# AU302PDF51 register map
File version: 1.0
Registers are 32-bit, access per field, reset 0x0 unless marked. A register's access mark holds for its fields unless they carry their own. Offsets are from the block's base; [hi:lo] are bit positions; {n}, {i} and the like mark numbered series.

## CRG — CRG_PERIAPBIF peripheral interface
Base 0x10000000
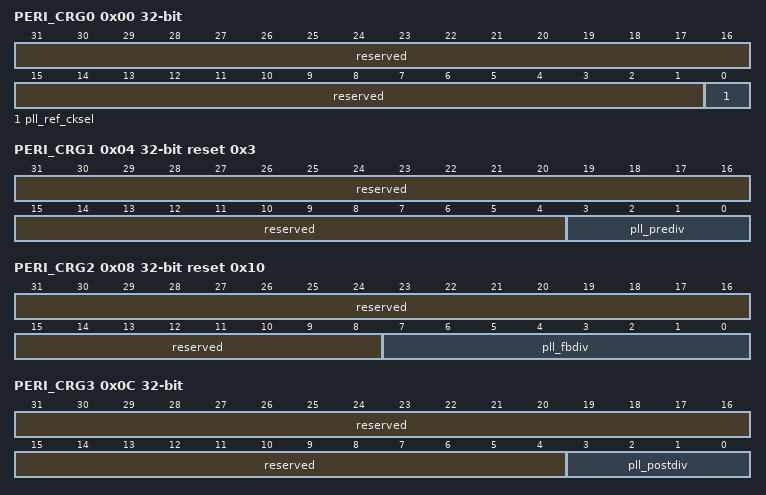
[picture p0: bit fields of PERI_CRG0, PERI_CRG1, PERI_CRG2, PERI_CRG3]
0x00 PERI_CRG0 — pll寄存器0。
  [31:1] reserved ro — 保留。
  [0] pll_ref_cksel rw — PLL输入参考时钟clk_pll_ref时钟源选择信号： 0：选择clk_hosc； 1：选择clk_xtal。
0x04 PERI_CRG1 reset 0x3 — pll寄存器1。
  [31:4] reserved ro — 保留。
  [3:0] pll_prediv rw — PLL内部前置分频器分频比 0x0：1； 0x1：1； 0x2：2； 0x3：4； 其他：保留。
0x08 PERI_CRG2 reset 0x10 — pll寄存器2。
  [31:8] reserved ro — 保留。
  [7:0] pll_fbdiv rw — PLL内部反馈分频器分频比 允许配置范围8'd6 ~ 8'd63； 其他：保留。
0x0C PERI_CRG3 — pll寄存器3。
  [31:4] reserved ro — 保留。
  [3:0] pll_postdiv rw — PLL内部后置分频器分频比 0x0：1； 0x1：2； 0x2：4； 0x3：8； 0x4：16； 0x5：32； 其他：保留。
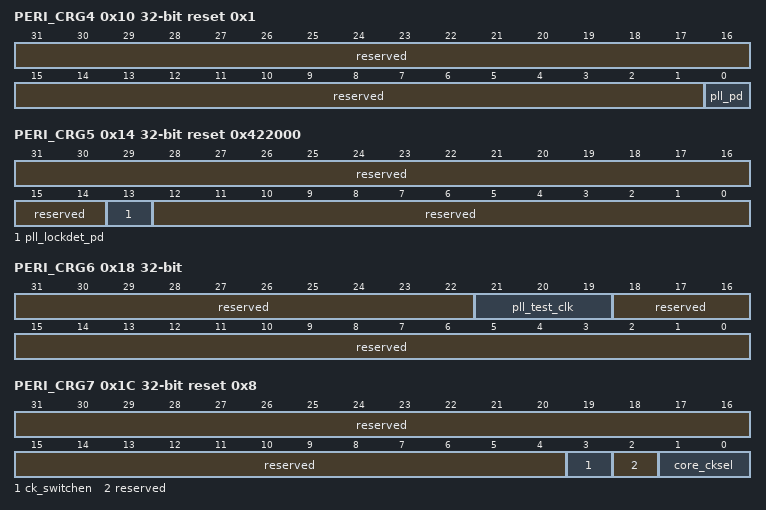
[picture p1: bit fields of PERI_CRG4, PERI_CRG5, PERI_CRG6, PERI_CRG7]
0x10 PERI_CRG4 reset 0x1 — pll寄存器4。
  [31:1] reserved ro — 保留。
  [0] pll_pd rw — PLL使能控制 0：PLL上电使能； 1：PLL下电关闭。
0x14 PERI_CRG5 reset 0x422000 — pll寄存器5。
  [31:14] reserved ro — 保留。
  [13] pll_lockdet_pd rw — PLL锁定检测控制 0：PLL锁定检测使能； 1：PLL锁定检测关闭。 PLL下电关闭时时需关闭锁定检测，PLL上电使能后需打开锁定检测。
  [12:0] reserved ro — 保留。
0x18 PERI_CRG6 — pll寄存器6。
  [31:22] reserved ro — 保留。
  [21:19] pll_test_clk rw — CLKOUT_TEST测试口输出功能选择： 3'd0:FPFD 信号 3'd1:CKFB 信号 3'd2:锁定检测器输出信号 3'd3:FOUTPOSTDIV的128分频输出信号 3'd4:未分配，输出0 3'd5:未分配，输出0 3'd6:未分配，输出0 3'd7:未分配，输出0
  [18:0] reserved ro — 保留；
0x1C PERI_CRG7 reset 0x8 — 系统时钟控制寄存器。
  [31:4] reserved ro — 保留。
  [3] ck_switchen rw — 时钟切换交互功能使能： 0：不使能； 1：使能。
  [2] reserved ro — 保留；
  [1:0] core_cksel rw — core_cksel信号： 00：选择clk_hosc； 01：旋转clk_xtal； 10：选择clk_pll； 11:保留。
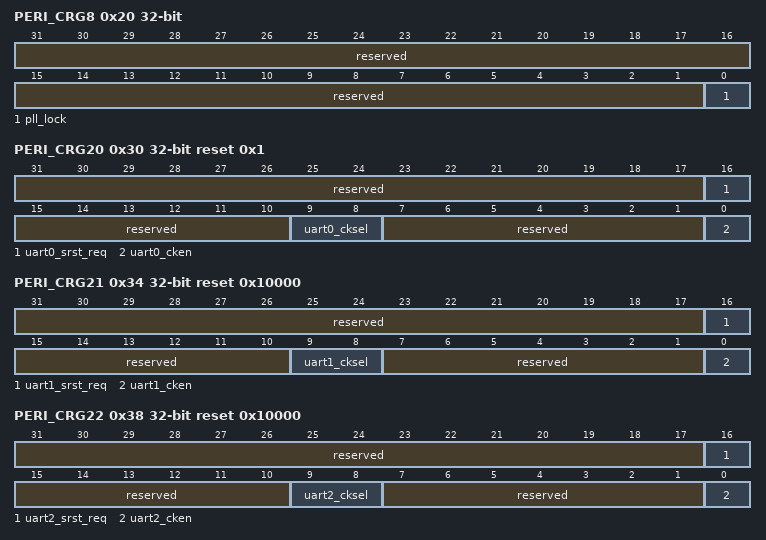
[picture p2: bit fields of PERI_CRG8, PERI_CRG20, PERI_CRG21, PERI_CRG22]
0x20 PERI_CRG8 ro — pll输出lock信息寄存器。
  [31:1] reserved — 保留。
  [0] pll_lock — pll lock信号：
0x30 PERI_CRG20 reset 0x1 — uart0时钟及软复位控制寄存器。
  [31:17] reserved ro — 保留。
  [16] uart0_srst_req rw — uart0软复位请求： 0：不复位； 1：复位。
  [15:10] reserved ro — 保留。
  [9:8] uart0_cksel rw — uart0时钟选择信号： 00：选择clk_ls时钟； 01：选择clk_ls/2时钟； 10：选择clk_ls/4时钟； 11：选择clk_ls/8时钟。
  [7:1] reserved ro — 保留。
  [0] uart0_cken rw — uart0时钟门控： 0：关断； 1：打开。
0x34 PERI_CRG21 reset 0x10000 — uart1时钟及软复位控制寄存器。
  [31:17] reserved ro — 保留。
  [16] uart1_srst_req rw — uart1软复位请求： 0：不复位； 1：复位。
  [15:10] reserved ro — 保留。
  [9:8] uart1_cksel rw — uart1时钟选择信号： 00：选择clk_ls时钟； 01：选择clk_ls/2时钟； 10：选择clk_ls/4时钟； 11：选择clk_ls/8时钟。
  [7:1] reserved ro — 保留。
  [0] uart1_cken rw — uart1时钟门控： 0：关断； 1：打开。
0x38 PERI_CRG22 reset 0x10000 — uart2时钟及软复位控制寄存器。
  [31:17] reserved ro — 保留。
  [16] uart2_srst_req rw — uart2软复位请求： 0：不复位； 1：复位。
  [15:10] reserved ro — 保留。
  [9:8] uart2_cksel rw — uart2时钟选择信号： 00：选择clk_ls时钟； 01：选择clk_ls/2时钟； 10：选择clk_ls/4时钟； 11：选择clk_ls/8时钟。
  [7:1] reserved ro — 保留。
  [0] uart2_cken rw — uart2时钟门控： 0：关断； 1：打开。
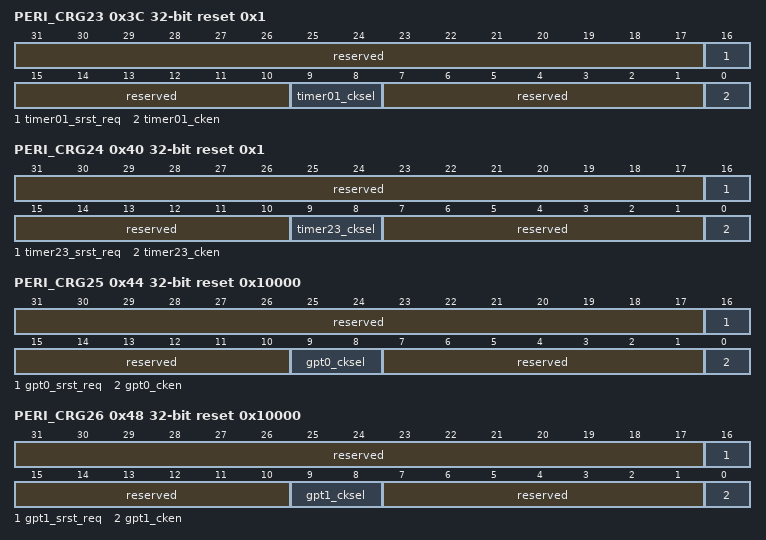
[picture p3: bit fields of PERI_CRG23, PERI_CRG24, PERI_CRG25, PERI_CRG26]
0x3C PERI_CRG23 reset 0x1 — timer0/1时钟及软复位控制寄存器。
  [31:17] reserved ro — 保留。
  [16] timer01_srst_req rw — timer0/1软复位请求： 0：不复位； 1：复位。
  [15:10] reserved ro — 保留。
  [9:8] timer01_cksel rw — timer0/1时钟选择信号： 00：选择clk_ls时钟； 01：选择clk_ls/2时钟； 10：选择clk_ls/4时钟； 11：选择clk_ls/8时钟。
  [7:1] reserved ro — 保留。
  [0] timer01_cken rw — timer0/1时钟门控： 0：关断； 1：打开。
0x40 PERI_CRG24 reset 0x1 — timer2/3时钟及软复位控制寄存器。
  [31:17] reserved ro — 保留。
  [16] timer23_srst_req rw — timer2/3软复位请求： 0：不复位； 1：复位。
  [15:10] reserved ro — 保留。
  [9:8] timer23_cksel rw — timer2/3时钟选择信号： 00：选择clk_ls时钟； 01：选择clk_ls/2时钟； 10：选择clk_ls/4时钟； 11：选择clk_ls/8时钟。
  [7:1] reserved ro — 保留。
  [0] timer23_cken rw — timer2/3时钟门控： 0：关断； 1：打开。
0x44 PERI_CRG25 reset 0x10000 — gpt0时钟及软复位控制寄存器。
  [31:17] reserved ro — 保留。
  [16] gpt0_srst_req rw — gpt0软复位请求： 0：不复位； 1：复位。
  [15:10] reserved ro — 保留。
  [9:8] gpt0_cksel rw — gpt0时钟选择信号： 00：选择clk_ls时钟； 01：选择clk_ls/2时钟； 10：选择clk_ls/4时钟； 11：选择clk_ls/8时钟。
  [7:1] reserved ro — 保留。
  [0] gpt0_cken rw — gpt0时钟门控： 0：关断； 1：打开。
0x48 PERI_CRG26 reset 0x10000 — gpt1时钟及软复位控制寄存器。
  [31:17] reserved ro — 保留。
  [16] gpt1_srst_req rw — gpt1软复位请求： 0：不复位； 1：复位。
  [15:10] reserved ro — 保留。
  [9:8] gpt1_cksel rw — gpt1时钟选择信号： 00：选择clk_ls时钟； 01：选择clk_ls/2时钟； 10：选择clk_ls/4时钟； 11：选择clk_ls/8时钟。
  [7:1] reserved ro — 保留。
  [0] gpt1_cken rw — gpt1时钟门控： 0：关断； 1：打开。
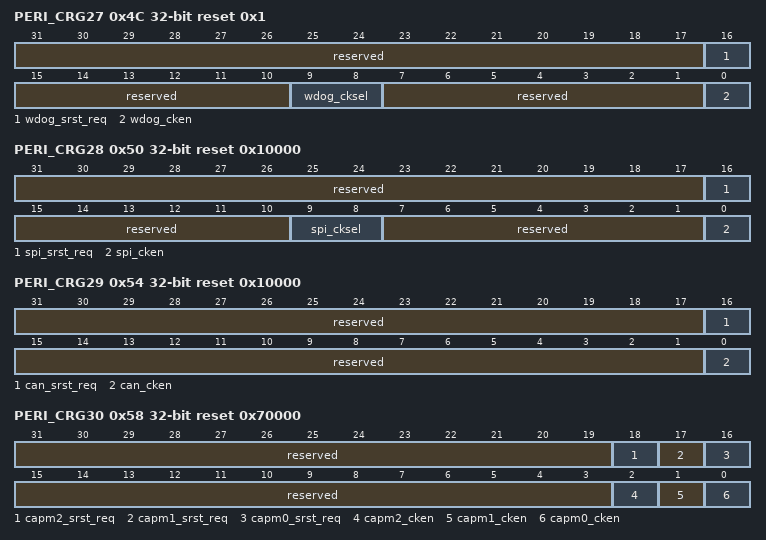
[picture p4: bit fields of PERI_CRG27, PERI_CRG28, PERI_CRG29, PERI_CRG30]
0x4C PERI_CRG27 reset 0x1 — wdog时钟及软复位控制寄存器。
  [31:17] reserved ro — 保留。
  [16] wdog_srst_req rw — wdog软复位请求： 0：不复位； 1：复位。
  [15:10] reserved ro — 保留。
  [9:8] wdog_cksel rw — wdog时钟选择信号： 00：选择clk_ls时钟； 01：选择clk_ls/2时钟； 10：选择clk_ls/4时钟； 11：选择clk_ls/8时钟。
  [7:1] reserved ro — 保留。
  [0] wdog_cken rw — wdog时钟门控： 0：关断； 1：打开。
0x50 PERI_CRG28 reset 0x10000 — spi时钟及软复位控制寄存器。
  [31:17] reserved ro — 保留。
  [16] spi_srst_req rw — spi软复位请求： 0：不复位； 1：复位。
  [15:10] reserved ro — 保留。
  [9:8] spi_cksel rw — spi时钟选择信号： 00：选择clk_ls时钟； 01：选择clk_ls/2时钟； 10：选择clk_ls/4时钟； 11：选择clk_ls/8时钟。
  [7:1] reserved ro — 保留。
  [0] spi_cken rw — spi时钟门控： 0：关断； 1：打开。
0x54 PERI_CRG29 reset 0x10000 — can时钟及软复位控制寄存器。
  [31:17] reserved ro — 保留。
  [16] can_srst_req rw — can软复位请求： 0：不复位； 1：复位。
  [15:1] reserved ro — 保留。
  [0] can_cken rw — can时钟门控： 0：关断； 1：打开。
0x58 PERI_CRG30 reset 0x70000 — capm时钟及软复位控制寄存器。
  [31:19] reserved ro — 保留。
  [18] capm2_srst_req rw — capm2软复位请求： 0：不复位； 1：复位。
  [17] capm1_srst_req rw — capm1软复位请求： 0：不复位； 1：复位。
  [16] capm0_srst_req rw — capm0软复位请求： 0：不复位； 1：复位。
  [15:3] reserved ro — 保留。
  [2] capm2_cken rw — capm2时钟门控： 0：关断； 1：打开。
  [1] capm1_cken rw — capm1时钟门控： 0：关断； 1：打开。
  [0] capm0_cken rw — capm0时钟门控： 0：关断； 1：打开。
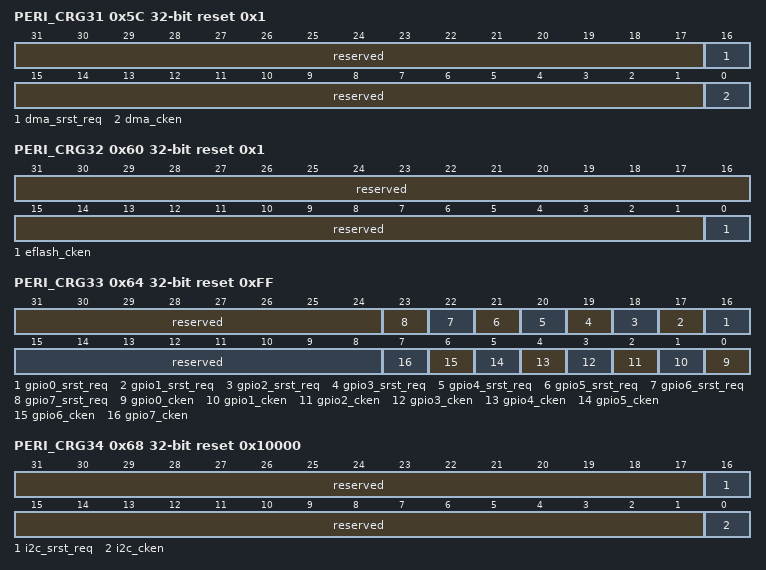
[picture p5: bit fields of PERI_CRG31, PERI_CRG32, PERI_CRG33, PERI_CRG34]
0x5C PERI_CRG31 reset 0x1 — dma时钟及软复位控制寄存器。
  [31:17] reserved ro — 保留。
  [16] dma_srst_req rw — dma软复位请求： 0：不复位； 1：复位。
  [15:1] reserved ro — 保留。
  [0] dma_cken rw — dma时钟门控： 0：关断； 1：打开。
0x60 PERI_CRG32 reset 0x1 — eflash时钟及软复位控制寄存器。
  [31:1] reserved ro — 保留。
  [0] eflash_cken rw — eflash时钟门控： 0：关断； 1：打开。
0x64 PERI_CRG33 reset 0xFF — gpio时钟及软复位控制寄存器。
  [31:24] reserved ro — 保留。
  [n+16] gpio{n}_srst_req rw (n=0..7) — gpio{n}软复位请求： 0：不复位； 1：复位。
  [15:8] reserved ro — 保留。
  [n] gpio{n}_cken rw (n=0..7) — gpio{n}时钟门控： 0：关断； 1：打开。
0x68 PERI_CRG34 reset 0x10000 — i2c时钟及软复位控制寄存器。
  [31:17] reserved ro — 保留。
  [16] i2c_srst_req rw — i2c软复位请求： 0：不复位； 1：复位。
  [15:1] reserved ro — 保留。
  [0] i2c_cken rw — i2c时钟门控： 0：关断； 1：打开。
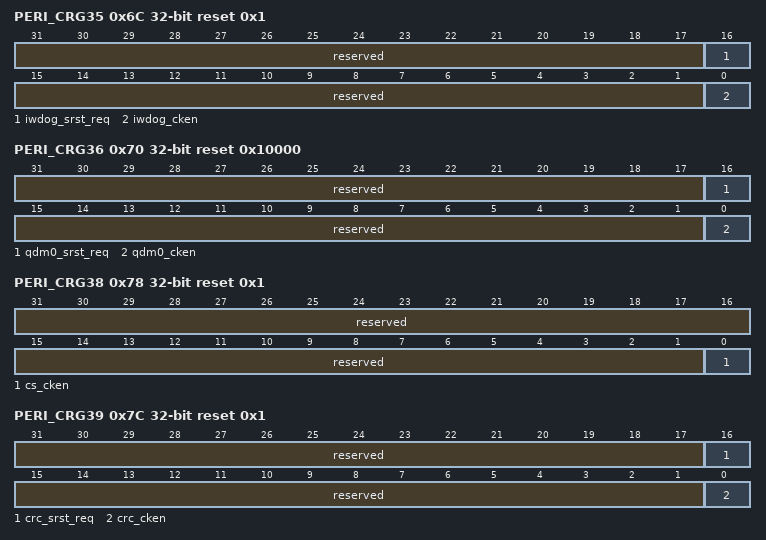
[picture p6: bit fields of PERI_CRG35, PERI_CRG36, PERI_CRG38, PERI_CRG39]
0x6C PERI_CRG35 reset 0x1 — iwdog时钟及软复位控制寄存器。
  [31:17] reserved ro — 保留。
  [16] iwdog_srst_req rw — iwdog软复位请求： 0：不复位； 1：复位。
  [15:1] reserved ro — 保留。
  [0] iwdog_cken rw — iwdog时钟门控： 0：关断； 1：打开。
0x70 PERI_CRG36 reset 0x10000 — qdm时钟及软复位控制寄存器。
  [31:17] reserved ro — 保留。
  [16] qdm0_srst_req rw — qdm软复位请求： 0：不复位； 1：复位。
  [15:1] reserved ro — 保留。
  [0] qdm0_cken rw — qdm时钟门控： 0：关断； 1：打开。
0x78 PERI_CRG38 reset 0x1 — coresight时钟及软复位控制寄存器。
  [31:1] reserved ro — 保留。
  [0] cs_cken rw — coresight自动时钟门控功能控制： 0：自动门控功能打开关断； 1：自动门控功能关闭。
0x7C PERI_CRG39 reset 0x1 — crc时钟及软复位控制寄存器。
  [31:17] reserved ro — 保留。
  [16] crc_srst_req rw — crc软复位请求： 0：不复位； 1：复位。
  [15:1] reserved ro — 保留。
  [0] crc_cken rw — crc时钟门控： 0：关断； 1：打开。
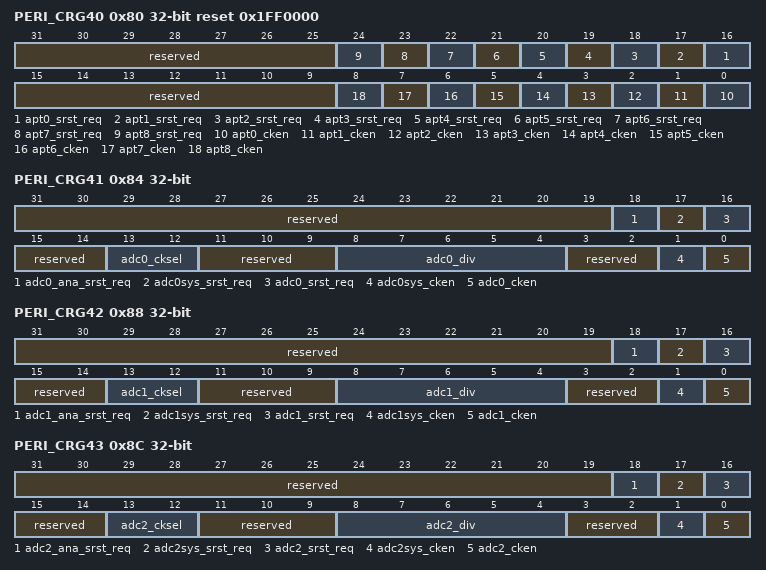
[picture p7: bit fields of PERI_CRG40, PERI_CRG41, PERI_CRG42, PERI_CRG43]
0x80 PERI_CRG40 reset 0x1FF0000 — APT时钟及软复位控制寄存器。
  [31:25] reserved ro — 保留。
  [n+16] apt{n}_srst_req rw (n=0..8) — apt{n}软复位请求： 0：不复位； 1：复位。
  [15:9] reserved ro — 保留。
  [n] apt{n}_cken rw (n=0..8) — apt{n}时钟门控： 0：关断； 1：打开。
0x84 PERI_CRG41 — ADC0寄存器。
  [31:19] reserved ro — 保留。
  [18] adc0_ana_srst_req rw — adc0模拟部分软复位请求： 0：不复位； 1：复位。
  [17] adc0sys_srst_req rw — adc0控制器配置时钟域软复位请求： 0：不复位； 1：复位。
  [16] adc0_srst_req rw — adc0控制器采样时钟域软复位请求： 0：不复位； 1：复位。
  [15:14] reserved ro — 保留。
  [13:12] adc0_cksel rw — adc0采样时钟源选择信号。 00：选择clk_hosc时钟； 01：选择clk_xtal时钟； 1x：选择pll时钟经过adc0_div分频后的时钟。
  [11:9] reserved ro — 保留。
  [8:4] adc0_div rw — adc0采样时钟分频参数，配置范围为[0-15]。 adc0_cksel = 2'b1x时，adc0采样时钟频率为： Fclk_vco/(adc0_div[4:1] + 0.5*adc0_div[0] +1)
  [3:2] reserved ro — 保留。
  [1] adc0sys_cken rw — adc0控制器配置时钟门控： 0：关断； 1：打开。
  [0] adc0_cken rw — adc0控制器采样时钟门控： 0：关断； 1：打开。
0x88 PERI_CRG42 — ADC1寄存器。
  [31:19] reserved ro — 保留。
  [18] adc1_ana_srst_req rw — adc1模拟部分软复位请求： 0：不复位； 1：复位。
  [17] adc1sys_srst_req rw — adc1控制器配置时钟域软复位请求： 0：不复位； 1：复位。
  [16] adc1_srst_req rw — adc1控制器采样时钟域软复位请求： 0：不复位； 1：复位。
  [15:14] reserved ro — 保留。
  [13:12] adc1_cksel rw — adc1采样时钟源选择信号。 00：选择clk_hosc时钟； 01：选择clk_xtal时钟； 1x：选择pll时钟经过adc1_div分频后的时钟。
  [11:9] reserved ro — 保留。
  [8:4] adc1_div rw — adc1采样时钟分频参数，配置范围为[0-15]。 adc1_cksel = 2'b1x时，adc1采样时钟频率为： Fclk_vco/(adc1_div[4:1] + 0.5*adc1_div[0] +1)
  [3:2] reserved ro — 保留。
  [1] adc1sys_cken rw — adc1控制器配置时钟门控： 0：关断； 1：打开。
  [0] adc1_cken rw — adc1控制器采样时钟门控： 0：关断； 1：打开。
0x8C PERI_CRG43 — ADC2寄存器。
  [31:19] reserved ro — 保留。
  [18] adc2_ana_srst_req rw — adc2模拟部分软复位请求： 0：不复位； 1：复位。
  [17] adc2sys_srst_req rw — adc2控制器配置时钟域软复位请求： 0：不复位； 1：复位。
  [16] adc2_srst_req rw — adc2控制器采样时钟域软复位请求： 0：不复位； 1：复位。
  [15:14] reserved ro — 保留。
  [13:12] adc2_cksel rw — adc2采样时钟源选择信号。 00：选择clk_hosc时钟； 01：选择clk_xtal时钟； 1x：选择clk_vco经过adc2_div分频后的时钟。
  [11:9] reserved ro — 保留。
  [8:4] adc2_div rw — adc2采样时钟分频参数，配置范围为[0-15]。 adc2_cksel = 2'b1x时，adc2采样时钟频率为： Fclk_vco/(adc2_div[4:1] + 0.5*adc2_div[0] +1)
  [3:2] reserved ro — 保留。
  [1] adc2sys_cken rw — adc2控制器配置时钟门控： 0：关断； 1：打开。
  [0] adc2_cken rw — adc2控制器采样时钟门控： 0：关断； 1：打开。
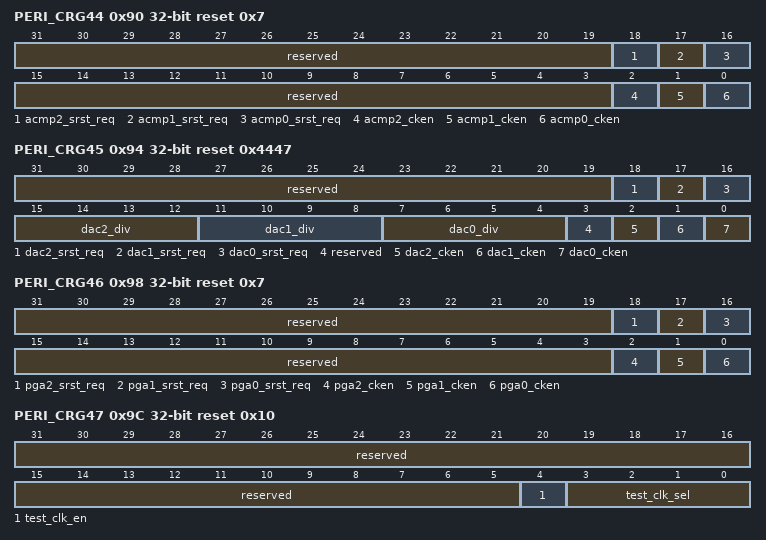
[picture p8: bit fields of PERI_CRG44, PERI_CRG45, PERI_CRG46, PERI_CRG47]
0x90 PERI_CRG44 reset 0x7 — ACMP时钟及软复位控制寄存器。
  [31:19] reserved ro — 保留。
  [18] acmp2_srst_req rw — acmp2控制器软复位请求： 0：不复位； 1：复位。
  [17] acmp1_srst_req rw — acmp1控制器软复位请求： 0：不复位； 1：复位。
  [16] acmp0_srst_req rw — acmp0控制器软复位请求： 0：不复位； 1：复位。
  [15:3] reserved ro — 保留。
  [2] acmp2_cken rw — acmp2控制器时钟门控： 0：关断； 1：打开。
  [1] acmp1_cken rw — acmp1控制器时钟门控： 0：关断； 1：打开。
  [0] acmp0_cken rw — acmp0控制器时钟门控： 0：关断； 1：打开。
0x94 PERI_CRG45 reset 0x4447 — DAC寄存器。
  [31:19] reserved ro — 保留。
  [18] dac2_srst_req rw — dac2控制器软复位请求： 0：不复位； 1：复位。
  [17] dac1_srst_req rw — dac1控制器软复位请求： 0：不复位； 1：复位。
  [16] dac0_srst_req rw — dac0控制器软复位请求： 0：不复位； 1：复位。
  [15:12] dac2_div rw — dac2模拟部分工作时钟分频参数 时钟频率为Fclk_pll_ref/(dac2_div+1)。
  [11:8] dac1_div rw — dac1模拟部分工作时钟分频参数 时钟频率为Fclk_pll_ref/(dac1_div+1)。
  [7:4] dac0_div rw — dac0模拟部分工作时钟分频参数 时钟频率为Fclk_pll_ref/(dac0_div+1)。
  [3] reserved ro — 保留。
  [2] dac2_cken rw — dac2控制器时钟门控： 0：关断； 1：打开。
  [1] dac1_cken rw — dac1控制器时钟门控： 0：关断； 1：打开。
  [0] dac0_cken rw — dac0控制器时钟门控： 0：关断； 1：打开。
0x98 PERI_CRG46 reset 0x7 — PGA时钟及软复位控制寄存器。
  [31:19] reserved ro — 保留。
  [18] pga2_srst_req rw — pga2控制器软复位请求： 0：不复位； 1：复位。
  [17] pga1_srst_req rw — pga1控制器软复位请求： 0：不复位； 1：复位。
  [16] pga0_srst_req rw — pga0控制器软复位请求： 0：不复位； 1：复位。
  [15:3] reserved ro — 保留。
  [2] pga2_cken rw — pga2控制器时钟门控： 0：关断； 1：打开。
  [1] pga1_cken rw — pga1控制器时钟门控： 0：关断； 1：打开。
  [0] pga0_cken rw — pga0控制器时钟门控： 0：关断； 1：打开。
0x9C PERI_CRG47 reset 0x10 — 时钟输出控制寄存器。
  [31:5] reserved ro — 保留。
  [4] test_clk_en rw — test_clk_en 0：不使能； 1：使能。
  [3:0] test_clk_sel rw — test_clk时钟选择： 0x0：clk_pll/1024； 0x1：clk_hosc； 0x2：clk_losc； 0x3：clk_xtal； 0x4：clk_dac0； 0x5：clk_dac1； 0x6：clk_dac2； 0x7：clk_adc0； 0x8：clk_adc1； 0x9：clk_adc2； 其它：保留。
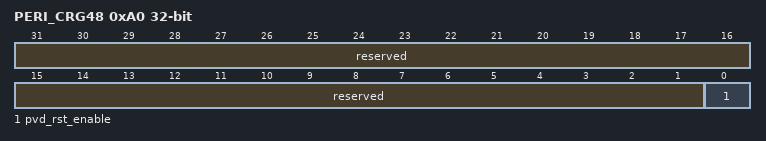
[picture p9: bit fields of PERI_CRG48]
0xA0 PERI_CRG48 — PVD复位控制寄存器。
  [31:1] reserved ro — 保留。
  [0] pvd_rst_enable rw — pvd复位使能 0：不使能； 1：使能。
